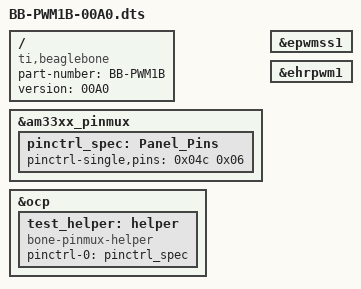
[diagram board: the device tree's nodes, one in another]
/dts-v1/;
/plugin/;

/{
compatible = "ti,beaglebone", "ti,beaglebone-black";
part-number = "BB-PWM1B";
version = "00A0";

fragment@0 {
target = <&am33xx_pinmux>;
__overlay__ {
pinctrl_spec: Panel_Pins {
pinctrl-single,pins = <
0x04c 0x06 /* P9_16 MODE4 ehrpwm1B PWM */
>;
};
};
};

fragment@1 {
target = <&ocp>;
__overlay__ {
test_helper: helper {
compatible = "bone-pinmux-helper";
pinctrl-names = "default";
pinctrl-0 = <&pinctrl_spec>;
status = "okay";
};
};
};

fragment@2 {
target = <&epwmss1>;
__overlay__ {
status = "okay";
};
};

fragment@3 {
target = <&ehrpwm1>;
__overlay__ {
status = "okay";
};
};

};
